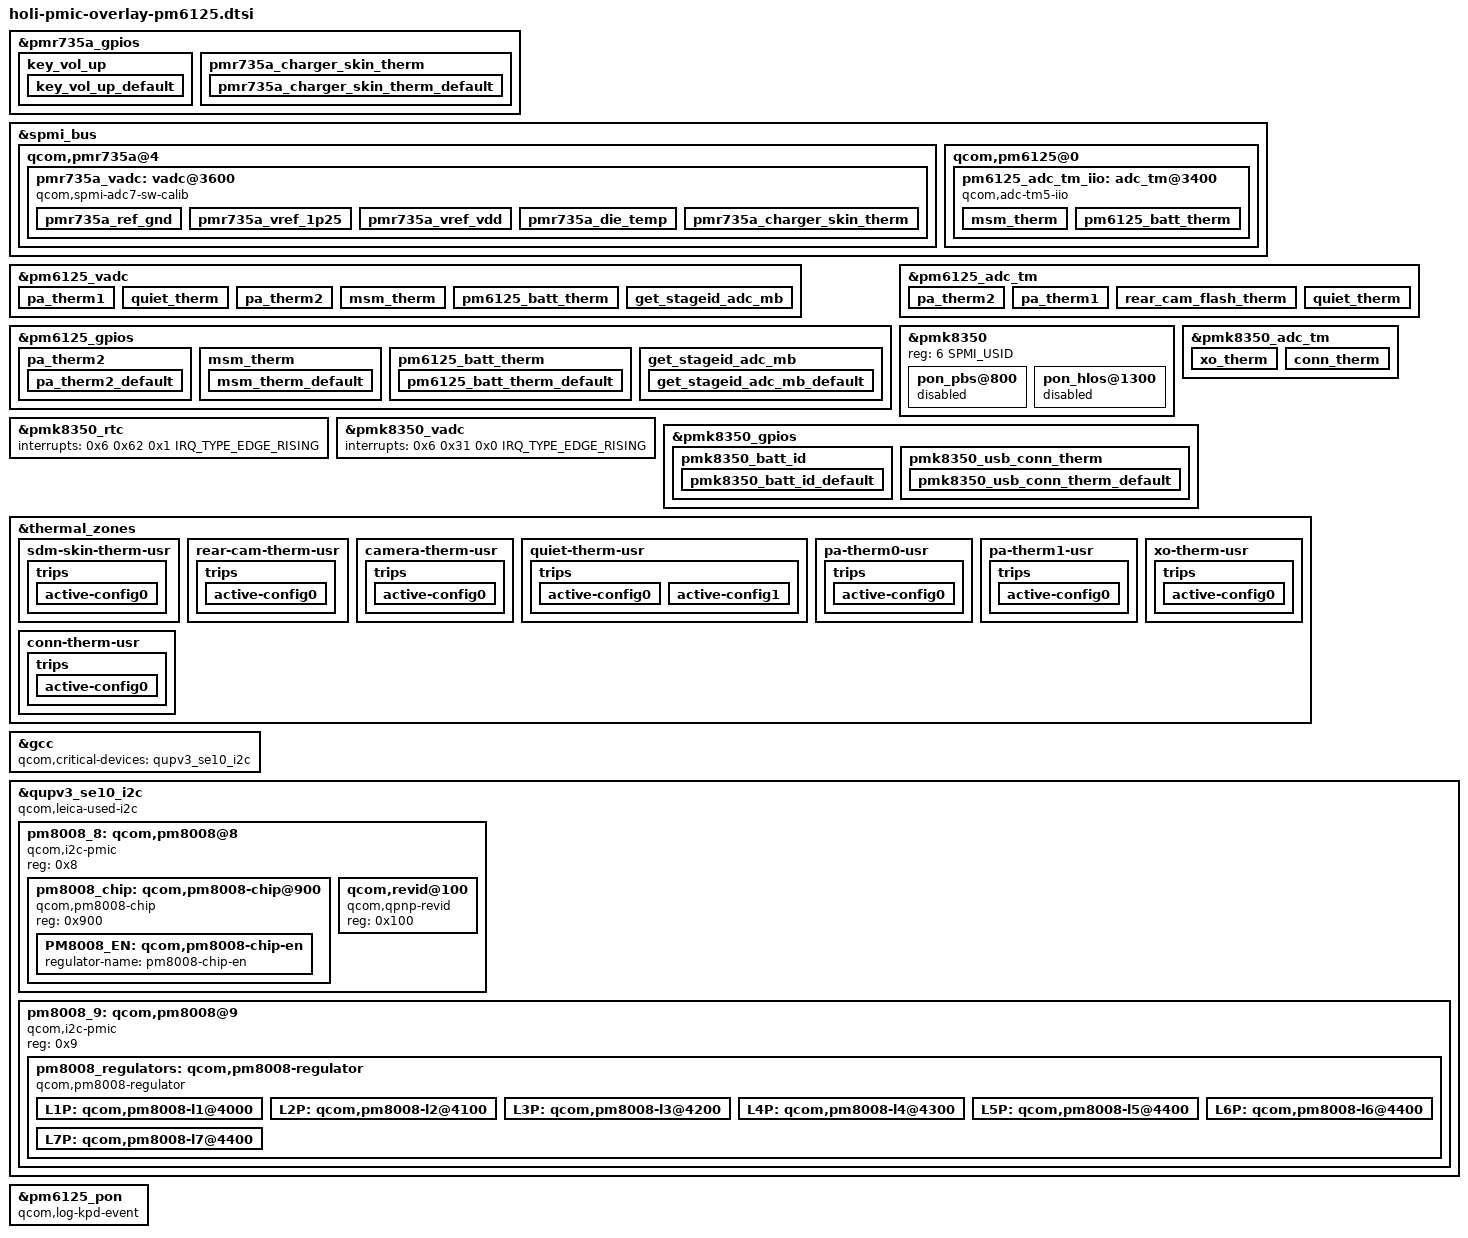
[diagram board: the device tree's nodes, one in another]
#include <dt-bindings/pinctrl/qcom,pmic-gpio.h>
#include <dt-bindings/interrupt-controller/irq.h>

#include "pm6125.dtsi"
#include "pmr735a.dtsi"

#define PMK8350_SID	6

#include "pmk8350.dtsi"

&pmr735a_gpios {
	key_vol_up {
		key_vol_up_default: key_vol_up_default {
			pins = "gpio1";
			function = "normal";
			input-enable;
			bias-pull-up;
			power-source = <1>;
		};
	};
	pmr735a_charger_skin_therm {
	pmr735a_charger_skin_therm_default: pmr735a_charger_skin_therm_default {
			pins = "gpio3";
			bias-high-impedance;
		};
	};
};

&spmi_bus {
	qcom,pmr735a@4 {
		/* Example configuration to enable PMR735A VADC in standalone mode */
		pmr735a_vadc: vadc@3600 {
			compatible = "qcom,spmi-adc7-sw-calib";
			reg = <0x3600>, <0x3900>;
			reg-names = "adc5-sw-calib-pbs-base", "adc5-sw-calib-cmn-base";
			#address-cells = <1>;
			#size-cells = <0>;
			interrupts = <0x4 0x36 0x0 IRQ_TYPE_EDGE_RISING>;
			interrupt-names = "eoc";
			#io-channel-cells = <1>;
			io-channel-ranges;
			status = "ok";

			/* PMR735a Channel nodes */
			pmr735a_ref_gnd {
				reg = <ADC7_REF_GND>;
				label = "pmr735a_ref_gnd";
				qcom,pre-scaling = <1 1>;
				qcom,no-cal;
			};

			pmr735a_vref_1p25 {
				reg = <ADC7_1P25VREF>;
				label = "pmr735a_vref_1p25";
				qcom,pre-scaling = <1 1>;
				qcom,no-cal;
			};

			pmr735a_vref_vdd {
				reg = <ADC7_VREF_VADC>;
				label = "pmr735a_vref_vdd";
				qcom,pre-scaling = <1 1>;
				qcom,no-cal;
			};

			pmr735a_die_temp {
				reg = <ADC7_DIE_TEMP>;
				label = "pmr735a_die_temp";
				qcom,pre-scaling = <1 1>;
			};
			pmr735a_charger_skin_therm {
				reg = <ADC7_GPIO3_100K_PU>;
				label = "pmr735a_charger_skin_therm";
				qcom,ratiometric;
				qcom,hw-settle-time = <200>;
				qcom,pre-scaling = <1 1>;
				bias-high-impedance;
			};
		};
	};
};

&pm6125_vadc {
	pinctrl-names = "default";
	pinctrl-0 = <
			&pa_therm2_default
			&msm_therm_default
			&pm6125_batt_therm_default
			&get_stageid_adc_mb_default>;

	/delete-node/ xo_therm;

	pa_therm1 {
		reg = <ADC5_AMUX_THM1_100K_PU>;
		label = "pa_therm1";
		qcom,ratiometric;
		qcom,hw-settle-time = <200>;
		qcom,pre-scaling = <1 1>;
	};

	quiet_therm {
		reg = <ADC5_AMUX_THM2_100K_PU>;
		label = "quiet_therm";
		qcom,ratiometric;
		qcom,hw-settle-time = <200>;
		qcom,pre-scaling = <1 1>;
	};

	pa_therm2 {
		reg = <ADC5_GPIO4_100K_PU>;
		label = "pa_therm2";
		qcom,ratiometric;
		qcom,hw-settle-time = <200>;
		qcom,pre-scaling = <1 1>;
	};

	msm_therm {
		reg = <ADC5_GPIO1_100K_PU>;
		label = "msm_therm";
		qcom,ratiometric;
		qcom,hw-settle-time = <200>;
		qcom,pre-scaling = <1 1>;
	};

	pm6125_batt_therm {
		reg = <ADC5_GPIO2_100K_PU>;
		label = "pm6125_batt_therm";
		qcom,ratiometric;
		qcom,hw-settle-time = <200>;
		qcom,pre-scaling = <1 1>;
	};

	get_stageid_adc_mb {
		reg = <ADC5_GPIO3_100K_PU>;
		label = "get_stageid_adc_mb";
		qcom,ratiometric;
		qcom,hw-settle-time = <200>;
		qcom,pre-scaling = <1 1>;
	};
};

&pm6125_gpios {
	pa_therm2 {
		pa_therm2_default: pa_therm2_default {
			pins = "gpio7";
			bias-high-impedance;
		};
	};

	msm_therm {
		msm_therm_default: msm_therm_default {
			pins = "gpio3";
			bias-high-impedance;
		};
	};

	pm6125_batt_therm {
		pm6125_batt_therm_default: pm6125_batt_therm_default {
			pins = "gpio4";
			bias-high-impedance;
		};
	};

	get_stageid_adc_mb {
		get_stageid_adc_mb_default: get_stageid_adc_mb_default {
			pins = "gpio6";
			bias-high-impedance;
		};
	};
};

&pm6125_adc_tm {
	io-channels = <&pm6125_vadc ADC5_GPIO4_100K_PU>,
			<&pm6125_vadc ADC5_AMUX_THM1_100K_PU>,
			<&pm6125_vadc ADC5_GPIO3_100K_PU>,
			<&pm6125_vadc ADC5_AMUX_THM2_100K_PU>;

	/* Channel nodes */
	pa_therm2 {
		reg = <ADC5_GPIO4_100K_PU>;
		qcom,ratiometric;
		qcom,hw-settle-time = <200>;
	};

	pa_therm1 {
		reg = <ADC5_AMUX_THM1_100K_PU>;
		qcom,ratiometric;
		qcom,hw-settle-time = <200>;
	};

	rear_cam_flash_therm {
		reg = <ADC5_GPIO3_100K_PU>;
		qcom,ratiometric;
		qcom,hw-settle-time = <200>;
	};

	quiet_therm {
		reg = <ADC5_AMUX_THM2_100K_PU>;
		qcom,ratiometric;
		qcom,hw-settle-time = <200>;
	};
};

&spmi_bus {
	qcom,pm6125@0 {
		pm6125_adc_tm_iio: adc_tm@3400 {
			compatible = "qcom,adc-tm5-iio";
			reg = <0x3400>;
			#thermal-sensor-cells = <1>;
			#address-cells = <1>;
			#size-cells = <0>;
			io-channels = <&pm6125_vadc ADC5_GPIO1_100K_PU>,
					<&pm6125_vadc ADC5_GPIO2_100K_PU>;

			msm_therm {
				reg = <ADC5_GPIO1_100K_PU>;
				qcom,ratiometric;
				qcom,hw-settle-time = <200>;
			};

			pm6125_batt_therm {
				reg = <ADC5_GPIO2_100K_PU>;
				qcom,ratiometric;
				qcom,hw-settle-time = <200>;
			};
		};
	};
};

&pmk8350 {
	reg = <6 SPMI_USID>;

	pon_pbs@800 {
		status = "disabled";
	};

	pon_hlos@1300 {
		status = "disabled";
	};
};

&pmk8350_rtc {
	interrupts = <0x6 0x62 0x1 IRQ_TYPE_EDGE_RISING>;
};

&pmk8350_vadc {
	interrupts = <0x6 0x31 0x0 IRQ_TYPE_EDGE_RISING>;

	/delete-node/ pm8350_ref_gnd;
	/delete-node/ pm8350_vref_1p25;
	/delete-node/ pm8350_die_temp;
	/delete-node/ pm8350_vph_pwr;

	/delete-node/ pm8350b_ref_gnd;
	/delete-node/ pm8350b_vref_1p25;
	/delete-node/ pm8350b_die_temp;
	/delete-node/ pm8350b_vph_pwr;
	/delete-node/ pm8350b_vbat_sns;

	/delete-node/ pmr735a_ref_gnd;
	/delete-node/ pmr735a_vref_1p25;
	/delete-node/ pmr735a_die_temp;

	/delete-node/ pmr735b_ref_gnd;
	/delete-node/ pmr735b_vref_1p25;
	/delete-node/ pmr735b_die_temp;
};

&pmk8350_adc_tm {
	interrupts = <0x6 0x34 0x0 IRQ_TYPE_EDGE_RISING>;
	io-channels = <&pmk8350_vadc PMK8350_ADC7_AMUX_THM1_100K_PU
		        &pmk8350_vadc PMK8350_ADC7_AMUX_THM4_100K_PU>;

	xo_therm {
		reg = <PMK8350_ADC7_AMUX_THM1_100K_PU>;
		qcom,ratiometric;
		qcom,hw-settle-time = <200>;
	};

	conn_therm{
		reg = <PMK8350_ADC7_AMUX_THM4_100K_PU>;
		qcom,ratiometric;
		qcom,hw-settle-time = <200>;
	};
};

&pmk8350_gpios {
	pmk8350_batt_id {
		pmk8350_batt_id_default: pmk8350_batt_id_default {
			pins = "gpio1";
			bias-high-impedance;
		};
	};

	pmk8350_usb_conn_therm {
		pmk8350_usb_conn_therm_default: pmk8350_usb_conn_therm_default {
			pins = "gpio3";
			bias-high-impedance;
		};
	};
};

&thermal_zones {
	sdm-skin-therm-usr {
		polling-delay-passive = <0>;
		polling-delay = <0>;
		thermal-governor = "user_space";
		thermal-sensors = <&pm6125_adc_tm_iio ADC5_GPIO1_100K_PU>;
		wake-capable-sensor;
		trips {
			active-config0 {
				temperature = <125000>;
				hysteresis = <1000>;
				type = "passive";
			};
		};
	};

	rear-cam-therm-usr {
		polling-delay-passive = <0>;
		polling-delay = <0>;
		thermal-governor = "user_space";
		thermal-sensors = <&pm6125_adc_tm_iio ADC5_GPIO2_100K_PU>;
		wake-capable-sensor;
		trips {
			active-config0 {
				temperature = <125000>;
				hysteresis = <1000>;
				type = "passive";
			};
		};
	};

	camera-therm-usr {
		polling-delay-passive = <0>;
		polling-delay = <0>;
		thermal-governor = "user_space";
		thermal-sensors = <&pm6125_adc_tm ADC5_GPIO3_100K_PU>;
		wake-capable-sensor;
		trips {
			active-config0 {
				temperature = <125000>;
				hysteresis = <1000>;
				type = "passive";
			};
		};
	};

	quiet-therm-usr {
		polling-delay-passive = <0>;
		polling-delay = <0>;
		thermal-governor = "user_space";
		thermal-sensors = <&pm6125_adc_tm ADC5_AMUX_THM2_100K_PU>;
		wake-capable-sensor;
		trips {
			active-config0 {
				temperature = <125000>;
				hysteresis = <1000>;
				type = "passive";
			};

			active-config1 {
				temperature = <125000>;
				hysteresis = <1000>;
				type = "passive";
			};
		};
	};

	pa-therm0-usr {
		polling-delay-passive = <0>;
		polling-delay = <0>;
		thermal-governor = "user_space";
		thermal-sensors = <&pm6125_adc_tm ADC5_AMUX_THM1_100K_PU>;
		wake-capable-sensor;
		trips {
			active-config0 {
				temperature = <125000>;
				hysteresis = <1000>;
				type = "passive";
			};
		};
	};

	pa-therm1-usr {
		polling-delay-passive = <0>;
		polling-delay = <0>;
		thermal-governor = "user_space";
		thermal-sensors = <&pm6125_adc_tm ADC5_GPIO4_100K_PU>;
		wake-capable-sensor;
		trips {
			active-config0 {
				temperature = <125000>;
				hysteresis = <1000>;
				type = "passive";
			};
		};
	};

	xo-therm-usr {
		polling-delay-passive = <0>;
		polling-delay = <0>;
		thermal-governor = "user_space";
		thermal-sensors = <&pmk8350_adc_tm PMK8350_ADC7_AMUX_THM1_100K_PU>;
		wake-capable-sensor;
		trips {
			active-config0 {
				temperature = <125000>;
				hysteresis = <1000>;
				type = "passive";
			};
		};
	};
	
	conn-therm-usr{
		polling-delay-passive = <0>;
		polling-delay = <0>;
		thermal-governor = "user_space";
		thermal-sensors = <&pmk8350_adc_tm PMK8350_ADC7_AMUX_THM4_100K_PU>;
		wake-capable-sensor;
		trips {
			active-config0 {
				temperature = <125000>;
				hysteresis = <1000>;
				type = "passive";
			};
		};
	
	};
};

/*
 * Each QUP device that's a parent to PMIC must be listed as a critical device
 * to GCC
 */
&gcc {
	qcom,critical-devices = <&qupv3_se10_i2c>;
};

&qupv3_se10_i2c {
	#address-cells = <1>;
	#size-cells = <0>;
	status = "ok";

	qcom,leica-used-i2c;
	pm8008_8: qcom,pm8008@8 {
		compatible = "qcom,i2c-pmic";
		reg = <0x8>;
		#address-cells = <1>;
		#size-cells = <0>;
		//pinctrl-names = "default";
		//pinctrl-0 = <&pm8008_active>;

		pm8008_chip: qcom,pm8008-chip@900 {
			compatible = "qcom,pm8008-chip";
			reg = <0x900>;

			PM8008_EN: qcom,pm8008-chip-en {
				regulator-name = "pm8008-chip-en";
			};
		};

		qcom,revid@100 {
			compatible = "qcom,qpnp-revid";
			reg = <0x100>;
		};
	};

	pm8008_9: qcom,pm8008@9 {
		compatible = "qcom,i2c-pmic";
		reg = <0x9>;
		#address-cells = <1>;
		#size-cells = <0>;

		pm8008_regulators: qcom,pm8008-regulator {
			compatible = "qcom,pm8008-regulator";
			#address-cells = <1>;
			#size-cells = <0>;
			pm8008_en-supply = <&PM8008_EN>;

			vdd_l1_l2-supply = <&S6A>;
			vdd_l6-supply = <&S7A>;

			L1P: qcom,pm8008-l1@4000 {
				reg = <0x4000>;
				regulator-name = "pm8008_l1";
				regulator-min-microvolt = <1100000>;
				regulator-max-microvolt = <1300000>;
				qcom,min-dropout-voltage = <56000>;
				qcom,hpm-min-load = <0>;
			};

			L2P: qcom,pm8008-l2@4100 {
				reg = <0x4100>;
				regulator-name = "pm8008_l2";
				regulator-min-microvolt = <950000>;
				regulator-max-microvolt = <1150000>;
				qcom,min-dropout-voltage = <96000>;
				qcom,hpm-min-load = <0>;
			};

			L3P: qcom,pm8008-l3@4200 {
				reg = <0x4200>;
				regulator-name = "pm8008_l3";
				regulator-min-microvolt = <2700000>;
				regulator-max-microvolt = <2900000>;
				qcom,min-dropout-voltage = <168000>;
				qcom,hpm-min-load = <0>;
			};

			L4P: qcom,pm8008-l4@4300 {
				reg = <0x4300>;
				regulator-name = "pm8008_l4";
				regulator-min-microvolt = <2700000>;
				regulator-max-microvolt = <2900000>;
				qcom,min-dropout-voltage = <136000>;
				qcom,hpm-min-load = <0>;
			};

			L5P: qcom,pm8008-l5@4400 {
				reg = <0x4400>;
				regulator-name = "pm8008_l5";
				regulator-min-microvolt = <2700000>;
				regulator-max-microvolt = <2900000>;
				qcom,min-dropout-voltage = <240000>;
				qcom,hpm-min-load = <0>;
			};

			L6P: qcom,pm8008-l6@4400 {
				reg = <0x4500>;
				regulator-name = "pm8008_l6";
				regulator-min-microvolt = <1500000>;
				regulator-max-microvolt = <1900000>;
				qcom,min-dropout-voltage = <48000>;
				qcom,hpm-min-load = <0>;
			};

			L7P: qcom,pm8008-l7@4400 {
				reg = <0x4600>;
				regulator-name = "pm8008_l7";
				regulator-min-microvolt = <2700000>;
				regulator-max-microvolt = <2900000>;
				qcom,min-dropout-voltage = <96000>;
				qcom,hpm-min-load = <0>;
			};
		};
	};
};

&pm6125_pon {
	qcom,log-kpd-event;
};
